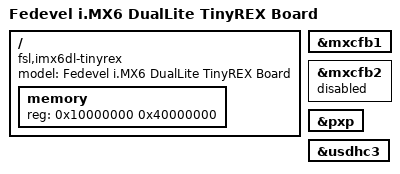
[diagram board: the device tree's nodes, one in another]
/*
 * Copyright (C) 2015 Voipac.
 *
 * This program is free software; you can redistribute it and/or modify
 * it under the terms of the GNU General Public License version 2 as
 * published by the Free Software Foundation.
 */

/dts-v1/;

#include "imx6dl.dtsi"
#include "imx6qdl-tinyrex.dtsi"

/ {
	model = "Fedevel i.MX6 DualLite TinyREX Board";
	compatible = "fsl,imx6dl-tinyrex", "fsl,imx6dl";

	memory {
		reg = <0x10000000 0x40000000>;
	};
};

&mxcfb1 {
	status = "okay";
};

&mxcfb2 {
	status = "disabled";
};

&pxp {
	status = "okay";
};

&usdhc3 {
	status = "okay";
};
